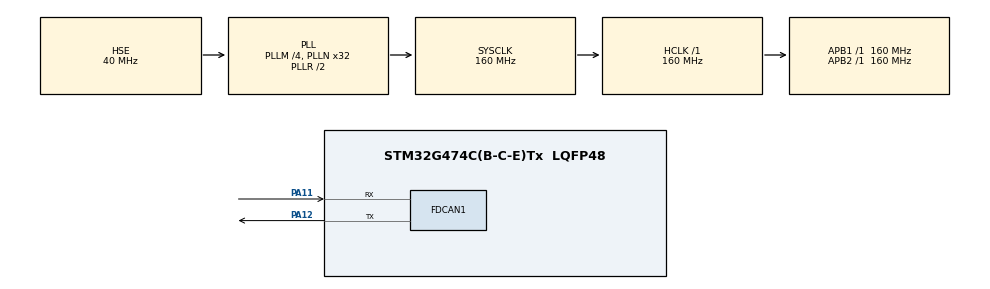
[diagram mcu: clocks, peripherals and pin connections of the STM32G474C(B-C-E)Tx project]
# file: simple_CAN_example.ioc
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FDCAN1.CalculateBaudRateNominal=1000000
FDCAN1.CalculateTimeBitNominal=1000
FDCAN1.CalculateTimeQuantumNominal=12.5
FDCAN1.ClockDivider=FDCAN_CLOCK_DIV2
FDCAN1.DataSyncJumpWidth=4
FDCAN1.DataTimeSeg1=15
FDCAN1.DataTimeSeg2=4
FDCAN1.FrameFormat=FDCAN_FRAME_FD_BRS
FDCAN1.NominalPrescaler=1
FDCAN1.NominalSyncJumpWidth=16
FDCAN1.NominalTimeSeg1=63
FDCAN1.NominalTimeSeg2=16
FDCAN1.StdFiltersNbr=1
Mcu.Family=STM32G4
Mcu.Name=STM32G474C(B-C-E)Tx
Mcu.Package=LQFP48
NVIC.FDCAN1_IT0_IRQn=true\:0\:0\:false\:false\:true\:true\:true\:true
NVIC.PriorityGroup=NVIC_PRIORITYGROUP_4
PA11.Mode=FDCAN_Activate
PA11.Signal=FDCAN1_RX
PA12.Mode=FDCAN_Activate
PA12.Signal=FDCAN1_TX
PF0-OSC_IN.Mode=HSE-External-Oscillator
PF0-OSC_IN.Signal=RCC_OSC_IN
PF1-OSC_OUT.Mode=HSE-External-Oscillator
PF1-OSC_OUT.Signal=RCC_OSC_OUT
ProjectManager.HeapSize=0x200
ProjectManager.StackSize=0x400
ProjectManager.TargetToolchain=CMake
RCC.ADC12Freq_Value=160000000
RCC.ADC345Freq_Value=160000000
RCC.AHBFreq_Value=160000000
RCC.APB1Freq_Value=160000000
RCC.APB1TimFreq_Value=160000000
RCC.APB2Freq_Value=160000000
RCC.APB2TimFreq_Value=160000000
RCC.CortexFreq_Value=160000000
RCC.EXTERNAL_CLOCK_VALUE=12288000
RCC.FDCANCLockSelection=RCC_FDCANCLKSOURCE_PLL
RCC.HCLKFreq_Value=160000000
RCC.HSE_VALUE=40000000
RCC.HSI48_VALUE=48000000
RCC.HSI_VALUE=16000000
RCC.LSE_VALUE=32768
RCC.PLLM=RCC_PLLM_DIV4
RCC.PLLN=32
RCC.PLLSourceVirtual=RCC_PLLSOURCE_HSE
RCC.SYSCLKFreq_VALUE=160000000
RCC.SYSCLKSource=RCC_SYSCLKSOURCE_PLLCLK
RCC.USBFreq_Value=160000000
RCC.VCOOutputFreq_Value=320000000
VP_SYS_VS_DBSignals.Mode=DisableDeadBatterySignals
board=custom

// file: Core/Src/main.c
/* USER CODE BEGIN Header */
/**
  ******************************************************************************
  * @file           : main.c
  * @brief          : Main program body
  ******************************************************************************
  * @attention
  *
  * Copyright (c) 2026 STMicroelectronics.
  * All rights reserved.
  *
  * This software is licensed under terms that can be found in the LICENSE file
  * in the root directory of this software component.
  * If no LICENSE file comes with this software, it is provided AS-IS.
  *
  ******************************************************************************
  */
/* USER CODE END Header */
#include "main.h"
#include "stm32g4xx_hal_fdcan.h"
#include <stdint.h>

FDCAN_HandleTypeDef hfdcan1;

/* USER CODE BEGIN PV */

uint8_t flag = 0;

const FDCAN_TxHeaderTypeDef TxHeader1 = {
  .Identifier = 0x12,
  .IdType = FDCAN_STANDARD_ID,
  .TxFrameType = FDCAN_DATA_FRAME,
  .DataLength = FDCAN_DLC_BYTES_2,
  .ErrorStateIndicator = FDCAN_ESI_ACTIVE,
  .BitRateSwitch = FDCAN_BRS_ON,
  .FDFormat = FDCAN_FD_CAN,
  .TxEventFifoControl = FDCAN_NO_TX_EVENTS,
  .MessageMarker = 0x0,
};

uint8_t TxData[2] = { 0, 2 };

/* USER CODE END PV */

void SystemClock_Config(void);
static void MX_GPIO_Init(void);
static void MX_FDCAN1_Init(void);

int main(void)
{

  /* MCU Configuration--------------------------------------------------------*/

  /* Reset of all peripherals, Initializes the Flash interface and the Systick. */
  HAL_Init();

  /* Configure the system clock */
  SystemClock_Config();

  /* Initialize all configured peripherals */
  MX_GPIO_Init();
  MX_FDCAN1_Init();

  /* Infinite loop */
  /* USER CODE BEGIN WHILE */
  while (1)
  {
    TxData[0] = flag;
    HAL_FDCAN_AddMessageToTxFifoQ(&hfdcan1, &TxHeader1, TxData);
    HAL_Delay(500);
    /* USER CODE END WHILE */

  }
}

void SystemClock_Config(void)
{
  RCC_OscInitTypeDef RCC_OscInitStruct = {0};
  RCC_ClkInitTypeDef RCC_ClkInitStruct = {0};

  /** Configure the main internal regulator output voltage
  */
  HAL_PWREx_ControlVoltageScaling(PWR_REGULATOR_VOLTAGE_SCALE1_BOOST);

  /** Initializes the RCC Oscillators according to the specified parameters
  * in the RCC_OscInitTypeDef structure.
  */
  RCC_OscInitStruct.OscillatorType = RCC_OSCILLATORTYPE_HSE;
  RCC_OscInitStruct.HSEState = RCC_HSE_ON;
  RCC_OscInitStruct.PLL.PLLState = RCC_PLL_ON;
  RCC_OscInitStruct.PLL.PLLSource = RCC_PLLSOURCE_HSE;
  RCC_OscInitStruct.PLL.PLLM = RCC_PLLM_DIV4;
  RCC_OscInitStruct.PLL.PLLN = 32;
  RCC_OscInitStruct.PLL.PLLP = RCC_PLLP_DIV2;
  RCC_OscInitStruct.PLL.PLLQ = RCC_PLLQ_DIV2;
  RCC_OscInitStruct.PLL.PLLR = RCC_PLLR_DIV2;
  if (HAL_RCC_OscConfig(&RCC_OscInitStruct) != HAL_OK)
  {
    Error_Handler();
  }

  /** Initializes the CPU, AHB and APB buses clocks
  */
  RCC_ClkInitStruct.ClockType = RCC_CLOCKTYPE_HCLK|RCC_CLOCKTYPE_SYSCLK
                              |RCC_CLOCKTYPE_PCLK1|RCC_CLOCKTYPE_PCLK2;
  RCC_ClkInitStruct.SYSCLKSource = RCC_SYSCLKSOURCE_PLLCLK;
  RCC_ClkInitStruct.AHBCLKDivider = RCC_SYSCLK_DIV1;
  RCC_ClkInitStruct.APB1CLKDivider = RCC_HCLK_DIV1;
  RCC_ClkInitStruct.APB2CLKDivider = RCC_HCLK_DIV1;

  if (HAL_RCC_ClockConfig(&RCC_ClkInitStruct, FLASH_LATENCY_4) != HAL_OK)
  {
    Error_Handler();
  }
}

static void MX_FDCAN1_Init(void)
{

  hfdcan1.Instance = FDCAN1;
  hfdcan1.Init.ClockDivider = FDCAN_CLOCK_DIV2;
  hfdcan1.Init.FrameFormat = FDCAN_FRAME_FD_BRS;
  hfdcan1.Init.Mode = FDCAN_MODE_NORMAL;
  hfdcan1.Init.AutoRetransmission = DISABLE;
  hfdcan1.Init.TransmitPause = DISABLE;
  hfdcan1.Init.ProtocolException = DISABLE;
  hfdcan1.Init.NominalPrescaler = 1;
  hfdcan1.Init.NominalSyncJumpWidth = 16;
  hfdcan1.Init.NominalTimeSeg1 = 63;
  hfdcan1.Init.NominalTimeSeg2 = 16;
  hfdcan1.Init.DataPrescaler = 1;
  hfdcan1.Init.DataSyncJumpWidth = 4;
  hfdcan1.Init.DataTimeSeg1 = 15;
  hfdcan1.Init.DataTimeSeg2 = 4;
  hfdcan1.Init.StdFiltersNbr = 1;
  hfdcan1.Init.ExtFiltersNbr = 0;
  hfdcan1.Init.TxFifoQueueMode = FDCAN_TX_FIFO_OPERATION;
  if (HAL_FDCAN_Init(&hfdcan1) != HAL_OK)
  {
    Error_Handler();
  }
  /* USER CODE BEGIN FDCAN1_Init 2 */

  //filter configuration
  const FDCAN_FilterTypeDef sFilterConfig = {
    .IdType = FDCAN_STANDARD_ID, //standard id not extended
    .FilterIndex = 0, //first filter, so index is 0
    .FilterType = FDCAN_FILTER_RANGE, //filter type, this case range
    .FilterConfig = FDCAN_FILTER_TO_RXFIFO0, //if filter passes send message to fifo0
    .FilterID1 = 0x0, // in range type all id passes from ID1 to ID2 so
    .FilterID2 = 0x7FF, //IDs between 0x0 and 0xFF pass
  };

  if(HAL_FDCAN_ConfigFilter(&hfdcan1, &sFilterConfig) != HAL_OK)
  {
    Error_Handler();
  }

  //Configuring global filter, aka what to do if a message passes no filter, more in function comment!
  if(HAL_FDCAN_ConfigGlobalFilter(&hfdcan1, FDCAN_FILTER_TO_RXFIFO0, FDCAN_FILTER_TO_RXFIFO0, FDCAN_FILTER_REJECT, FDCAN_FILTER_REJECT) != HAL_OK)
  {
    Error_Handler();
  }

  //in case of too many messages and RX_FIFO is full, what to do? REJECT/OVERWRITE
  if(HAL_FDCAN_ConfigRxFifoOverwrite(&hfdcan1, FDCAN_RX_FIFO0, FDCAN_RX_FIFO_OVERWRITE) != HAL_OK)
  {
    Error_Handler();
  }

  //CANFD TDCO and TDCF value
  HAL_FDCAN_ConfigTxDelayCompensation(&hfdcan1, 16, 33);
  //Enabling CANFD TDC
  HAL_FDCAN_EnableTxDelayCompensation(&hfdcan1);

  //Registering Interrupt routine for "New Message reception"
  HAL_FDCAN_ActivateNotification(&hfdcan1, FDCAN_FLAG_RX_FIFO0_NEW_MESSAGE, 0);
  /* Start the FDCAN module */
  if(HAL_FDCAN_Start(&hfdcan1) != HAL_OK)
  {
    Error_Handler();
  }

  /* USER CODE END FDCAN1_Init 2 */

}

static void MX_GPIO_Init(void)
{

  /* GPIO Ports Clock Enable */
  __HAL_RCC_GPIOF_CLK_ENABLE();
  __HAL_RCC_GPIOA_CLK_ENABLE();

}

void Error_Handler(void)
{
  __disable_irq();
  while (1)
  {
  }
}
